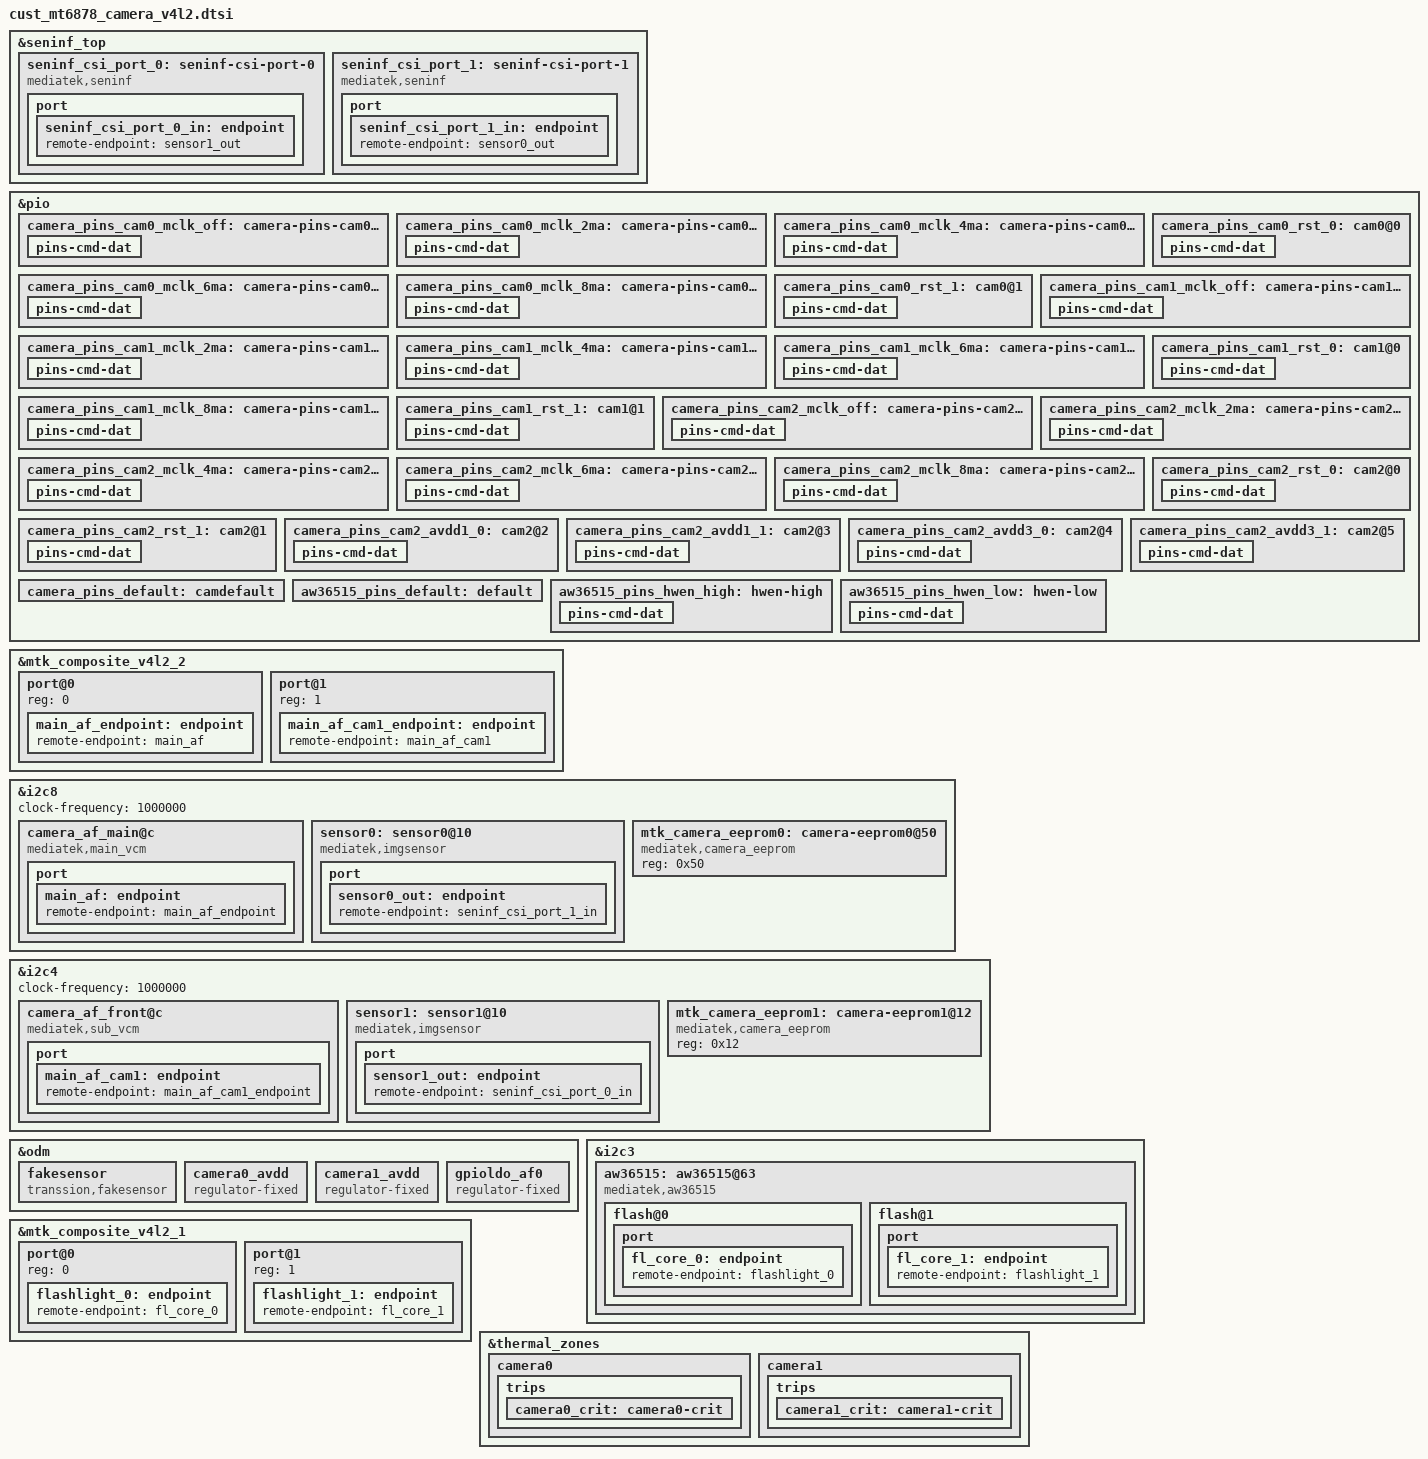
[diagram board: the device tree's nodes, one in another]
// SPDX-License-Identifier: GPL-2.0
/* Copyright (c) 2020 MediaTek Inc. */
#include <dt-bindings/clock/mt6878-clk.h>

&seninf_top {
	seninf_csi_port_0: seninf-csi-port-0 {
		compatible = "mediatek,seninf";
		csi-port = "0";
		dphy-settle-delay-dt = <17>;
		nvmem-cells = <&csi_efuse0>;
		nvmem-cell-names = "rg_csi";
		port {
			seninf_csi_port_0_in: endpoint {
				remote-endpoint = <&sensor1_out>;
			};
		};
	};

	seninf_csi_port_1: seninf-csi-port-1 {
		compatible = "mediatek,seninf";
		csi-port = "1";
		hs-trail-parameter = <0x20>;
		nvmem-cells = <&csi_efuse1>;
		nvmem-cell-names = "rg_csi";
		port {
			seninf_csi_port_1_in: endpoint {
				remote-endpoint = <&sensor0_out>;
			};
		};
	};
};


/* CAMERA GPIO standardization */
&pio {
	camera_pins_cam0_mclk_off: camera-pins-cam0-mclk-off {
		pins-cmd-dat {
			pinmux = <PINMUX_GPIO93__FUNC_GPIO93>;
			drive-strength = <1>;
		};
	};
	camera_pins_cam0_mclk_2ma: camera-pins-cam0-mclk-2ma {
		pins-cmd-dat {
			pinmux = <PINMUX_GPIO93__FUNC_CMMCLK1>;
			drive-strength = <0>;
		};
	};
	camera_pins_cam0_mclk_4ma: camera-pins-cam0-mclk-4ma {
		pins-cmd-dat {
			pinmux = <PINMUX_GPIO93__FUNC_CMMCLK1>;
			drive-strength = <1>;
		};
	};
	camera_pins_cam0_mclk_6ma: camera-pins-cam0-mclk-6ma {
		pins-cmd-dat {
			pinmux = <PINMUX_GPIO93__FUNC_CMMCLK1>;
			drive-strength = <2>;
		};
	};
	camera_pins_cam0_mclk_8ma: camera-pins-cam0-mclk-8ma {
		pins-cmd-dat {
			pinmux = <PINMUX_GPIO93__FUNC_CMMCLK1>;
			drive-strength = <3>;
		};
	};
	camera_pins_cam0_rst_0: cam0@0 {
		pins-cmd-dat {
			pinmux = <PINMUX_GPIO25__FUNC_GPIO25>;
			slew-rate = <1>;
			output-low;
		};
	};
	camera_pins_cam0_rst_1: cam0@1 {
		pins-cmd-dat {
			pinmux = <PINMUX_GPIO25__FUNC_GPIO25>;
			slew-rate = <1>;
			output-high;
		};
	};
	camera_pins_cam1_mclk_off: camera-pins-cam1-mclk-off {
		pins-cmd-dat {
			pinmux = <PINMUX_GPIO96__FUNC_GPIO96>;
			drive-strength = <1>;
		};
	};
	camera_pins_cam1_mclk_2ma: camera-pins-cam1-mclk-2ma {
		pins-cmd-dat {
			pinmux = <PINMUX_GPIO96__FUNC_CMMCLK4>;
			drive-strength = <0>;
		};
	};
	camera_pins_cam1_mclk_4ma: camera-pins-cam1-mclk-4ma {
		pins-cmd-dat {
			pinmux = <PINMUX_GPIO96__FUNC_CMMCLK4>;
			drive-strength = <1>;
		};
	};
	camera_pins_cam1_mclk_6ma: camera-pins-cam1-mclk-6ma {
		pins-cmd-dat {
			pinmux = <PINMUX_GPIO96__FUNC_CMMCLK4>;
			drive-strength = <2>;
		};
	};
	camera_pins_cam1_mclk_8ma: camera-pins-cam1-mclk-8ma {
		pins-cmd-dat {
			pinmux = <PINMUX_GPIO96__FUNC_CMMCLK4>;
			drive-strength = <3>;
		};
	};
	camera_pins_cam1_rst_0: cam1@0 {
		pins-cmd-dat {
			pinmux = <PINMUX_GPIO24__FUNC_GPIO24>;
			slew-rate = <1>;
			output-low;
		};
	};
	camera_pins_cam1_rst_1: cam1@1 {
		pins-cmd-dat {
			pinmux = <PINMUX_GPIO24__FUNC_GPIO24>;
			slew-rate = <1>;
			output-high;
		};
	};
	camera_pins_cam2_mclk_off: camera-pins-cam2-mclk-off {
		pins-cmd-dat {
			pinmux = <PINMUX_GPIO94__FUNC_GPIO94>;
			drive-strength = <1>;
		};
	};
	camera_pins_cam2_mclk_2ma: camera-pins-cam2-mclk-2ma {
		pins-cmd-dat {
			pinmux = <PINMUX_GPIO94__FUNC_CMMCLK2>;
			drive-strength = <0>;
		};
	};
	camera_pins_cam2_mclk_4ma: camera-pins-cam2-mclk-4ma {
		pins-cmd-dat {
			pinmux = <PINMUX_GPIO94__FUNC_CMMCLK2>;
			drive-strength = <1>;
		};
	};
	camera_pins_cam2_mclk_6ma: camera-pins-cam2-mclk-6ma {
		pins-cmd-dat {
			pinmux = <PINMUX_GPIO94__FUNC_CMMCLK2>;
			drive-strength = <2>;
		};
	};
	camera_pins_cam2_mclk_8ma: camera-pins-cam2-mclk-8ma {
		pins-cmd-dat {
			pinmux = <PINMUX_GPIO94__FUNC_CMMCLK2>;
			drive-strength = <3>;
		};
	};
	camera_pins_cam2_rst_0: cam2@0 {
		pins-cmd-dat {
			pinmux = <PINMUX_GPIO26__FUNC_GPIO26>;
			slew-rate = <1>;
			output-low;
		};
	};
	camera_pins_cam2_rst_1: cam2@1 {
		pins-cmd-dat {
			pinmux = <PINMUX_GPIO26__FUNC_GPIO26>;
			slew-rate = <1>;
			output-high;
		};
	};
	camera_pins_cam2_avdd1_0: cam2@2 {
		pins-cmd-dat {
			pinmux = <PINMUX_GPIO120__FUNC_GPIO120>;
			slew-rate = <1>;
			output-low;
		};
	};

	camera_pins_cam2_avdd1_1: cam2@3 {
		pins-cmd-dat {
			pinmux = <PINMUX_GPIO120__FUNC_GPIO120>;
			slew-rate = <1>;
			output-high;
		};
	};

	camera_pins_cam2_avdd3_0: cam2@4 {
		pins-cmd-dat {
			pinmux = <PINMUX_GPIO134__FUNC_GPIO134>;
			slew-rate = <1>;
			output-low;
		};
	};
	camera_pins_cam2_avdd3_1: cam2@5 {
		pins-cmd-dat {
			pinmux = <PINMUX_GPIO134__FUNC_GPIO134>;
			slew-rate = <1>;
			output-high;
		};
	};

	camera_pins_default: camdefault {
	};
};
/* CAMERA GPIO end */

&mtk_composite_v4l2_2 {
	#address-cells = <1>;
	#size-cells = <0>;
	port@0 {
		reg = <0>;
		main_af_endpoint: endpoint {
			remote-endpoint = <&main_af>;
		};
	};
	port@1 {
		reg = <1>;
		main_af_cam1_endpoint: endpoint {
			remote-endpoint = <&main_af_cam1>;
		};
	};
};

&i2c8 {
	status = "okay";
	clock-frequency = <1000000>;

	camera_af_main@c {
		compatible = "mediatek,main_vcm";
		reg = <0x0c>;
		vin-supply = <&gpioldo_af0>;
		port {
			main_af: endpoint {
				remote-endpoint = <&main_af_endpoint>;
			};
		};
	};

	sensor0: sensor0@10 {
		compatible = "mediatek,imgsensor";
		sensor-names = "s5kjn1_mipi_raw";
		reg = <0x10>;
		#thermal-sensor-cells = <0>;
		sensor-matecodes = "s5kjn1_17201906";
		pinctrl-names = "mclk_off",
				"mclk_2mA",
				"mclk_4mA",
				"mclk_6mA",
				"mclk_8mA",
				"rst_low",
				"rst_high";

		pinctrl-0 = <&camera_pins_cam0_mclk_off>;
		pinctrl-1 = <&camera_pins_cam0_mclk_2ma>;
		pinctrl-2 = <&camera_pins_cam0_mclk_4ma>;
		pinctrl-3 = <&camera_pins_cam0_mclk_6ma>;
		pinctrl-4 = <&camera_pins_cam0_mclk_8ma>;
		pinctrl-5 = <&camera_pins_cam0_rst_0>;
		pinctrl-6 = <&camera_pins_cam0_rst_1>;

		avdd-supply = <&camera0_avdd>;
		dvdd-supply = <&mt6363_vcn13>;
		dovdd-supply = <&mt6369_vant18>;

		clocks = <&topckgen_clk CLK_TOP_UVPLL192M_D32>,
			<&topckgen_clk CLK_TOP_UVPLL192M_D16>,
			<&topckgen_clk CLK_TOP_OSC_D20>,
			<&topckgen_clk CLK_TOP_UVPLL192M_D10>,
			<&topckgen_clk CLK_TOP_UVPLL192M_D8>,
			<&topckgen_clk CLK_TOP_TCK_26M_MX9>,
			<&topckgen_clk CLK_TOP_UNIVPLL_D6_D8>,
			<&topckgen_clk CLK_TOP_CAMTG2_SEL>;
		clock-names = "6", "12", "13", "19.2", "24", "26", "52", "mclk";


		status = "okay";
		port {
			sensor0_out: endpoint {
				remote-endpoint = <&seninf_csi_port_1_in>;
			};
		};
	};

	mtk_camera_eeprom0:camera-eeprom0@50 {
		compatible = "mediatek,camera_eeprom";
		reg = <0x50>;
		status = "okay";
	};
};

&i2c4 {
	status = "okay";
	clock-frequency = <1000000>;
	camera_af_front@c {
		compatible = "mediatek,sub_vcm";
		reg = <0x0c>;
		vin-supply = <&mt6369_vio28>;
		port {
			main_af_cam1: endpoint {
				remote-endpoint = <&main_af_cam1_endpoint>;
			};
		};
	};

	sensor1: sensor1@10 {
		compatible = "mediatek,imgsensor";
		sensor-names = "gc13a0_mipi_raw";
		reg = <0x10>;
		sensor-matecodes = "gc13a0_17201959";
		#thermal-sensor-cells = <0>;

		pinctrl-names = "mclk_off",
				"mclk_2mA",
				"mclk_4mA",
				"mclk_6mA",
				"mclk_8mA",
				"rst_low",
				"rst_high";
		pinctrl-0 = <&camera_pins_cam1_mclk_off>;
		pinctrl-1 = <&camera_pins_cam1_mclk_2ma>;
		pinctrl-2 = <&camera_pins_cam1_mclk_4ma>;
		pinctrl-3 = <&camera_pins_cam1_mclk_6ma>;
		pinctrl-4 = <&camera_pins_cam1_mclk_8ma>;
		pinctrl-5 = <&camera_pins_cam1_rst_0>;
		pinctrl-6 = <&camera_pins_cam1_rst_1>;

		avdd-supply = <&camera1_avdd>;
		dvdd-supply = <&mt6363_vufs12>;
		dovdd-supply = <&mt6369_vant18>;

		clocks = <&topckgen_clk CLK_TOP_UVPLL192M_D32>,
			<&topckgen_clk CLK_TOP_UVPLL192M_D16>,
			<&topckgen_clk CLK_TOP_OSC_D20>,
			<&topckgen_clk CLK_TOP_UVPLL192M_D10>,
			<&topckgen_clk CLK_TOP_UVPLL192M_D8>,
			<&topckgen_clk CLK_TOP_TCK_26M_MX9>,
			<&topckgen_clk CLK_TOP_UNIVPLL_D6_D8>,
			<&topckgen_clk CLK_TOP_CAMTG5_SEL>;
		clock-names = "6", "12", "13", "19.2", "24", "26", "52", "mclk";

		status = "okay";
		port {
			sensor1_out: endpoint {
				remote-endpoint = <&seninf_csi_port_0_in>;
			};
		};
	};

	mtk_camera_eeprom1:camera-eeprom1@12 {
		compatible = "mediatek,camera_eeprom";
		reg = <0x12>;
		status = "okay";
	};
};



&odm {
	fakesensor: fakesensor {
		compatible = "transsion,fakesensor";
		sensor_matecodes = "cdpt_17201874";
		sensor_index = "2";
		fakevin-supply = <&camera1_avdd>;
		fakesensor_output = <&pio 27 0x0>;
	};
	camera0_avdd: camera0_avdd {
		compatible = "regulator-fixed";
		regulator-name = "camera0_avdd";
		regulator-min-microvolt = <2800000>;
		regulator-max-microvolt = <2800000>;
		gpio = <&pio 23 0x0>;
		enable-active-high;
	};
	camera1_avdd: camera1_avdd {
		compatible = "regulator-fixed";
		regulator-name = "camera1_avdd";
		regulator-min-microvolt = <2800000>;
		regulator-max-microvolt = <2800000>;
		gpio = <&pio 3 0x0>;
		enable-active-high;
	};
	gpioldo_af0: gpioldo_af0 {
		compatible = "regulator-fixed";
		regulator-name = "gpioldo_af0";
		regulator-min-microvolt = <3300000>;
		regulator-max-microvolt = <3300000>;
		gpio = <&pio 10 0x0>;
		enable-active-high;
	};
};

&i2c3 {
	aw36515:aw36515@63 {
		compatible = "mediatek,aw36515";
		reg = <0x63>;
		pinctrl-names = "default", "hwen_high", "hwen_low";
		pinctrl-0 = <&aw36515_pins_default>;
		pinctrl-1 = <&aw36515_pins_hwen_high>;
		pinctrl-2 = <&aw36515_pins_hwen_low>;
		status = "okay";
		flash@0{
			reg = <1>;
			type = <1>;
			ct = <0>;
			part = <0>;
			port {
				fl_core_0: endpoint {
					remote-endpoint = <&flashlight_0>;
				};
			};
		};
		flash@1{
			reg = <0>;
			type = <0>;
			ct = <0>;
			part = <0>;
			port {
				fl_core_1: endpoint {
					remote-endpoint = <&flashlight_1>;
				};
			};
		};
	};
};


&pio {
	aw36515_pins_default: default {
	};
	aw36515_pins_hwen_high: hwen-high {
		pins-cmd-dat {
			pinmux = <PINMUX_GPIO153__FUNC_GPIO153>;
			slew-rate = <1>;
			output-high;
		};
	};
	aw36515_pins_hwen_low: hwen-low {
		pins-cmd-dat {
			pinmux = <PINMUX_GPIO153__FUNC_GPIO153>;
			slew-rate = <1>;
			output-low;
		};
	};
};


&mtk_composite_v4l2_1 {
	port@0 {
		reg = <0>;
		flashlight_0: endpoint {
			remote-endpoint = <&fl_core_0>;
		};
	};
	port@1 {
		reg = <1>;
		flashlight_1: endpoint {
			remote-endpoint = <&fl_core_1>;
		};
	};
};

&thermal_zones {
	camera0: camera0 {
		polling-delay = <0>; /* milliseconds */
		polling-delay-passive = <0>; /* milliseconds */
		thermal-sensors = <&sensor0>;
		trips {
			camera0_crit: camera0-crit {
				temperature = <120000>;
				hysteresis = <2000>;
				type = "passive";
			};
		};
	};
	camera1: camera1 {
		polling-delay = <0>; /* milliseconds */
		polling-delay-passive = <0>; /* milliseconds */
		thermal-sensors = <&sensor1>;
		trips {
			camera1_crit: camera1-crit {
				temperature = <120000>;
				hysteresis = <2000>;
				type = "passive";
			};
		};
	};
};

